# ATSAMRH707F18A device description
Architecture: CORTEX-M7; Family: SAMRH; Series: SAMRH707
Registers are 32-bit, read-write, no defined reset value unless marked. A register's access mark holds for its fields unless they carry their own. Offsets are from the block's base; [hi:lo] are bit positions; {n}, {i} and the like mark numbered series; 'fields as' and 'values as' point back to an identical list.

## FLEXRAMECC
Instances: FLEXRAMECC 0x40100600
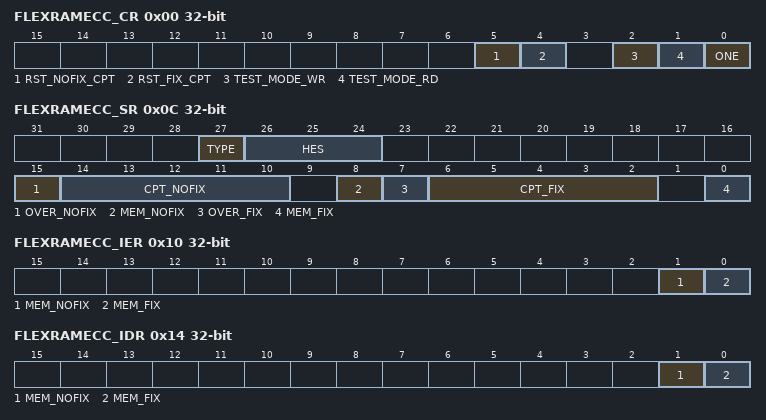
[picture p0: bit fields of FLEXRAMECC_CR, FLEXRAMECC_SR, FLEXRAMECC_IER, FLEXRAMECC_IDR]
0x00 FLEXRAMECC_CR — FLEXRAMECC Control Register
  [5] RST_NOFIX_CPT — reset the un-fixable error counter
  [4] RST_FIX_CPT — reset the fixable error counter
  [2] TEST_MODE_WR — test mode of ECC protection - write mode
  [1] TEST_MODE_RD — test mode of ECC protection - read mode
  [0] ONE — Shall be always write at '1'
0x04 FLEXRAMECC_TESTCB1 — FLEXRAMECC Test mode register 1
  [7:0] TCB1 — Test Check Bit
0x0C FLEXRAMECC_SR ro — FLEXRAMECC Status register
  [27] TYPE — write or read access
  [26:24] HES — Hardware Error Size
  [15] OVER_NOFIX — counter overflow
  [14:10] CPT_NOFIX — 5 bits counter
  [8] MEM_NOFIX — Un-fixable error status
  [7] OVER_FIX — counter overflow
  [6:2] CPT_FIX — 5 bits counter
  [0] MEM_FIX — Fixable error status
0x10 FLEXRAMECC_IER wo — FLEXRAMECC Interrupt Enable Register
  [1] MEM_NOFIX — Un-fixable error
  [0] MEM_FIX — Fixable error
0x14 FLEXRAMECC_IDR wo — FLEXRAMECC Interrupt Disable Register
  [1] MEM_NOFIX — un-fixable error
  [0] MEM_FIX — fixable error
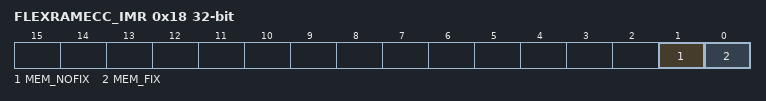
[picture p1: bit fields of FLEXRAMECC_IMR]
0x18 FLEXRAMECC_IMR ro — FLEXRAMECC Interrupt Mask Register
  [1] MEM_NOFIX — un-fixable error
  [0] MEM_FIX — fixable error
0x1C FLEXRAMECC_FAILAR ro — FLEXRAMECC Fail address register
  [31:0] ADDRESS — address of the error detected
0x20 FLEXRAMECC_FAILDR ro — FLEXRAMECC Fail data register
  [31:0] DATA — data error

## GPNVMBITS (HEFC module)
0x00 HEFC_GPNVM_TRIM_RC — HEFC GPNVM word RC trim CRC
  [31:0] RC_TRIM_CRC
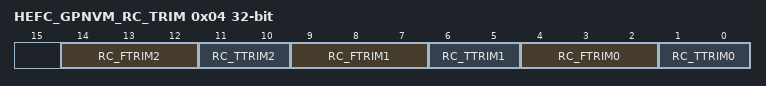
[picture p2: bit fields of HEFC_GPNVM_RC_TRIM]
0x04 HEFC_GPNVM_RC_TRIM — HEFC GPNVM word RC trim
  [14:12] RC_FTRIM2 — RC Frequency Trim 2
  [11:10] RC_TTRIM2 — RC Temperature Trim 2
  [9:7] RC_FTRIM1 — RC Frequency Trim 1
  [6:5] RC_TTRIM1 — RC Temperature Trim 1
  [4:2] RC_FTRIM0 — RC Frequency Trim 0
  [1:0] RC_TTRIM0 — RC Temperature Trim 0
0x04 HEFC_GPNVM_USR2 — User Word 2
  [31:0] USR_WORD2
0x04 HEFC_GPNVM_USR3 — User Word 3
  [31:0] USR_WORD3

## HEMC
Instances: HEMC 0x40080000
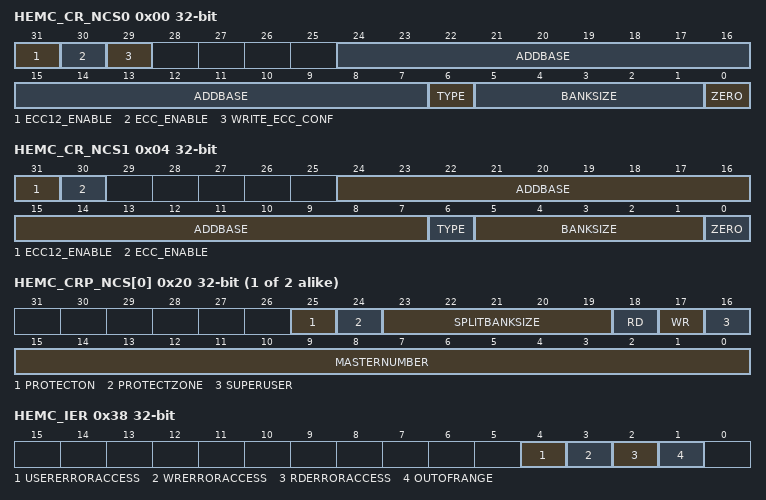
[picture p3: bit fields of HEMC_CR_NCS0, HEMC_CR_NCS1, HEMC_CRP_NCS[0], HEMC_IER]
0x00 HEMC_CR_NCS0 — HEMC Control Register NCS 0
  [31] ECC12_ENABLE — BCH ECC enable
  [30] ECC_ENABLE — ECC Protection Enable
  [29] WRITE_ECC_CONF — ECC Configuration Protection Enable
  [24:7] ADDBASE — relative base address of NCS area
  [6] TYPE — type of memory used
  [5:1] BANKSIZE
    0=_8KB (8Kbytes); 1=_16KB (16Kbytes); 2=_32KB (32Kbytes); 3=_64KB (64Kbytes); 4=_128KB (128Kbytes); 5=_256KB (256Kbytes); 6=_512KB (512Kbytes); 7=_1MB (1Mbytes); 8=_2MB (2Mbytes); 31=NOT_USED
  [0] ZERO — fixed to 0
0x04 HEMC_CR_NCS1 — HEMC Control Register NCS 1
  [31] ECC12_ENABLE — BCH ECC enable
  [30] ECC_ENABLE — ECC Protection Enable
  [24:7] ADDBASE — relative base address of NCS area
  [6] TYPE — type of memory used
  [5:1] BANKSIZE
    values as HEMC_CR_NCS0.BANKSIZE
  [0] ZERO — fixed to 0
0x18 HEMC_CTRL — HEMC Polarity Control register
  [0] POL — External control buffer active polarity
{0x20+4i} HEMC_CRP_NCS[{i}] (i=0..1) — HEMC Control Register Protection NCS
  [25] PROTECTON — protection activation
  [24] PROTECTZONE — select area protected
  [23:19] SPLITBANKSIZE — bank size internal separation
  [18] RD — Read Access
  [17] WR — Write Access
  [16] SUPERUSER — User or Superuser access
  [15:0] MASTERNUMBER — Master Number ID
0x38 HEMC_IER wo — HEMC Interrupt Enable Register
  [4] USERERRORACCESS — user or superuser access error
  [3] WRERRORACCESS — write access error
  [2] RDERRORACCESS — read access error
  [1] OUTOFRANGE
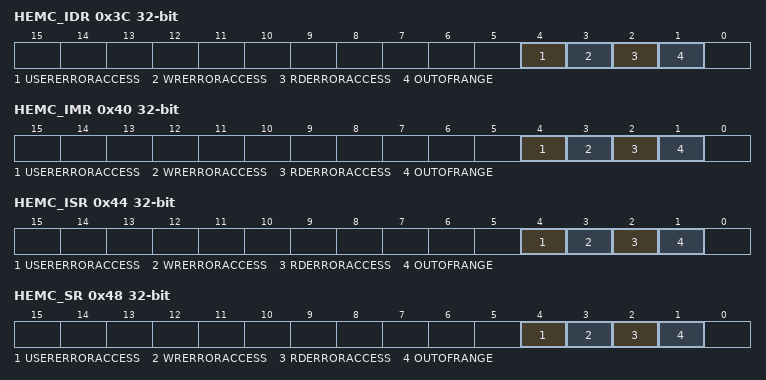
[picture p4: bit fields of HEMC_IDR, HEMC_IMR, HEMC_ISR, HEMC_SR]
0x3C HEMC_IDR wo — HEMC Interrupt Disable Register
  fields as HEMC_IER
0x40 HEMC_IMR ro — HEMC Interrupt Mask Register
  fields as HEMC_IER
0x44 HEMC_ISR ro — HEMC Interrupt Status Register
  [4] USERERRORACCESS — User or SuperUser Error Access
  [3] WRERRORACCESS — Write access error
  [2] RDERRORACCESS — read access error
  [1] OUTOFRANGE
0x48 HEMC_SR ro — HEMC Status Register
  [4] USERERRORACCESS — User or SuperUser Error Access
  [3] WRERRORACCESS — Write access error
  [2] RDERRORACCESS — Read access error
  [1] OUTOFRANGE
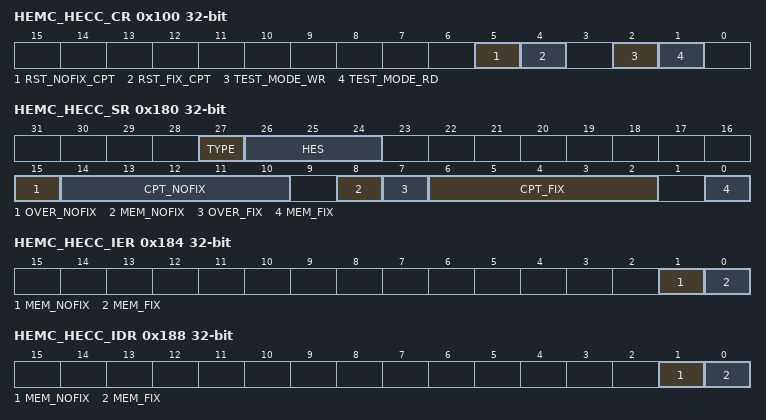
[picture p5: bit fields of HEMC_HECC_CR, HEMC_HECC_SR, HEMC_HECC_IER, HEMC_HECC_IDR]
0x100 HEMC_HECC_CR — HECC Control Register Channel 0 (HSMC)
  [5] RST_NOFIX_CPT — reset the un-fixable error counter
  [4] RST_FIX_CPT — reset the fixable error counter
  [2] TEST_MODE_WR — test mode of ECC protection - write mode
  [1] TEST_MODE_RD — test mode of ECC protection - read mode
0x140 HEMC_HECC_TESTCB — HECC Test mode Register Channel 0 (HSMC)
  [15:0] TCB1 — test check bit (16 bit)
0x180 HEMC_HECC_SR ro — HECC Status Register
  [27] TYPE — write or read access
  [26:24] HES — Hardware Error Size
  [15] OVER_NOFIX — counter overflow
  [14:10] CPT_NOFIX — 5 bits counter
  [8] MEM_NOFIX — Un-fixable error status
  [7] OVER_FIX — counter overflow
  [6:2] CPT_FIX — 5 bits counter
  [0] MEM_FIX — Fixable error status
0x184 HEMC_HECC_IER wo — HECC Interrupt Enable Register
  [1] MEM_NOFIX — Un-fixable error
  [0] MEM_FIX — Fixable error
0x188 HEMC_HECC_IDR wo — HECC Interrupt Disable Register
  [1] MEM_NOFIX — un-fixable error
  [0] MEM_FIX — fixable error
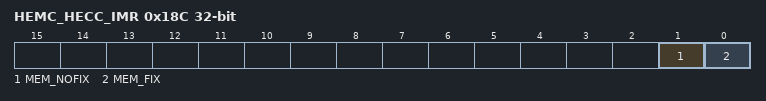
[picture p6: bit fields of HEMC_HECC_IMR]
0x18C HEMC_HECC_IMR ro — HECC Interrupt Mask Register
  [1] MEM_NOFIX — un-fixable error
  [0] MEM_FIX — fixable error
0x190 HEMC_HECC_FAILAR ro — HECC Fail address register
  [31:0] ADDRESS — address of the error detected
0x194 HEMC_HECC_FAILDR ro — HECC Fail data register
  [31:0] DATA — Data error detected
